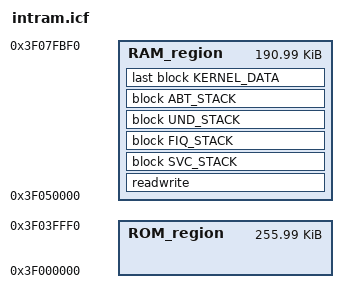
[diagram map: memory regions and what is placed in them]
/*###ICF### Section handled by ICF editor, don't touch! ****/
/*-Editor annotation file-*/
/* IcfEditorFile="$TOOLKIT_DIR$\config\ide\IcfEditor\a_v1_0.xml" */
/*-Specials-*/
define symbol __ICFEDIT_intvec_start__ = 0x3f000000;
/*-Memory Regions-*/
define symbol __ICFEDIT_region_ROM_start__   = 0x3f000000;
define symbol __ICFEDIT_region_ROM_end__     = 0x3f03fff0;
define symbol __ICFEDIT_region_RAM_start__   = 0x3f050000;
define symbol __ICFEDIT_region_RAM_end__     = 0x3f07fbf0;
/*-Sizes-*/
//define symbol __ICFEDIT_size_cstack__   = 0x400;
define symbol __ICFEDIT_size_svcstack__ = 0x400;
//define symbol __ICFEDIT_size_supstack__ = 0x40;
//define symbol __ICFEDIT_size_irqstack__ = 0x100;
define symbol __ICFEDIT_size_fiqstack__ = 0x40;
define symbol __ICFEDIT_size_undstack__ = 0x40;
define symbol __ICFEDIT_size_abtstack__ = 0x40;
//define symbol __ICFEDIT_size_heap__     = 0x200;
/**** End of ICF editor section. ###ICF###*/


define exported symbol __VECTOR_TABLE_ROM_START = 0x00000000;

define exported symbol __DEFAULT_PROCESSOR_NUMBER       = 1;
/* define exported symbol __DEFAULT_INTERRUPT_STACK_SIZE = 3000; //used BSP_DEFAULT_INTERRUPT_STACK_SIZE instead */
/* 64kB of  shared memory */
define exported symbol __SHARED_RAM_START               = 0x3f040000;
define exported symbol __SHARED_RAM_END                 = 0x3f04fff0;
define exported symbol __SRAM_POOL_START        = __ICFEDIT_region_RAM_start__;
define exported symbol __SRAM_POOL_END          = __ICFEDIT_region_RAM_end__;
define exported symbol __UNCACHED_DATA_START    = __ICFEDIT_region_RAM_start__;
define exported symbol __UNCACHED_DATA_END      = __ICFEDIT_region_RAM_end__;
/* mem_init writes a storeblock_struct at the end of kernel data, max size 32 bytes, so use 0x100 offset */
define exported symbol __BOOT_STACK_ADDRESS = __ICFEDIT_region_RAM_end__ - 0x100;

define exported symbol __KERNEL_DATA_END = __ICFEDIT_region_RAM_end__;

define memory mem with size = 4G;
define region ROM_region   = mem:[from __ICFEDIT_region_ROM_start__   to __ICFEDIT_region_ROM_end__];
define region RAM_region   = mem:[from __ICFEDIT_region_RAM_start__   to __ICFEDIT_region_RAM_end__];


//define block CSTACK    with alignment = 8, size = __ICFEDIT_size_cstack__   { };
define block SVC_STACK with alignment = 8, size = __ICFEDIT_size_svcstack__ { };
//define block SUP_STACK with alignment = 8, size = __ICFEDIT_size_supstack__ { };
//define block IRQ_STACK with alignment = 8, size = __ICFEDIT_size_irqstack__ { };
define block FIQ_STACK with alignment = 8, size = __ICFEDIT_size_fiqstack__ { };
define block UND_STACK with alignment = 8, size = __ICFEDIT_size_undstack__ { };
define block ABT_STACK with alignment = 8, size = __ICFEDIT_size_abtstack__ { };
//define block HEAP      with alignment = 8, size = __ICFEDIT_size_heap__     { };
define block KERNEL_DATA    with alignment = 32 { section .kernel_data };
define block VECTOR_TBL    with alignment = 32 { section .vector_tbl };

initialize by copy { readwrite };
do not initialize  { section .noinit };
do not initialize  { section .kernel_data };

place in ROM_region   { first block head { section STARTUP }, readonly, block VECTOR_TBL };
place in RAM_region   { readwrite, block SVC_STACK,  block FIQ_STACK, block UND_STACK, block ABT_STACK, last block KERNEL_DATA };

